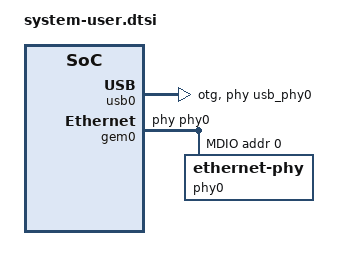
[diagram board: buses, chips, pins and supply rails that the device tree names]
/include/ "system-conf.dtsi"
/ {
	/*
	 * ULPI PHY for the PS USB controller (USB3320 on MIO28-39, PHY reset on MIO46).
	 */
	usb_phy0: phy0 {
		compatible = "ulpi-phy";
		#phy-cells = <0>;
		reg = <0xe0002000 0x1000>;
		view-port = <0x170>;
		drv-vbus;
	};
};

/*
 * Role is chosen in software (/sys/class/usb_role/ci_hdrc.0-role-switch/role, see zynqmini-usb-role).
 * With dr_mode unset the controller runs in OTG mode and senses ID/VBUS through the ULPI PHY; in that
 * mode, ID flickers due to poor board design, causing PHY clock/interface to die when the mode changes.
 * usb-role-switch masks the hardware sensing and fixes OTG mode by allowing manual switching.
 * The software default mode is gadget, allowing UsbAcm (Serial) and UsbNcm (Networking)
 */
&usb0 {
	usb-phy = <&usb_phy0>;
	dr_mode = "otg";
	usb-role-switch;
};

/*
 * SD1 (second TF slot, MIO10-15) has no card-detect line on this board. Without this the
 * kernel only looks for a card once at boot, so cards inserted later are never noticed.
 * broken-cd makes the MMC core poll the slot instead.
 */
&sdhci1 {
	broken-cd;
};

/*
 * QSPI flash (W25Q128FV, 16 MB, MIO1-6). The generated flash@0 node (system-conf.dtsi) has
 * partitions but no compatible flag and no reg flag, so no MTD device appears.
 * "jedec,spi-nor" lets the spi-nor driver identify the part by its JEDEC ID.
 */
&flash0 {
	compatible = "jedec,spi-nor";
	reg = <0>;
	spi-max-frequency = <50000000>;
	#address-cells = <1>;
	#size-cells = <1>;
};

/*
 * Ethernet PHY (RTL8211E on MDIO address 0). Specifies a phy-handle + mdio child for the macb driver to prevent fallback
 * to scanning all 32 MDIO addresses at probe time, which blocks the whole kernel init thread for 38 s on every boot.
 */
&gem0 {
	phy-handle = <&phy0>;
	mdio {
		#address-cells = <1>;
		#size-cells = <0>;
		phy0: ethernet-phy@0 {
			reg = <0>;
			device_type = "ethernet-phy";
		};
	};
};
